# XMC1100 register map
Vendor: Infineon; File version: 1.2.2 (Reference Manual v1.2)
CPU: CM0 r0p0, little endian, no MPU, no FPU, 2 interrupt priority bits
Registers are 32-bit, read-write, reset 0x0 unless marked. A register's access mark holds for its fields unless they carry their own. Offsets are from the block's base; [hi:lo] are bit positions; {n}, {i} and the like mark numbered series; 'fields as' and 'values as' point back to an identical list.

## PORT0
Base 0x40040000
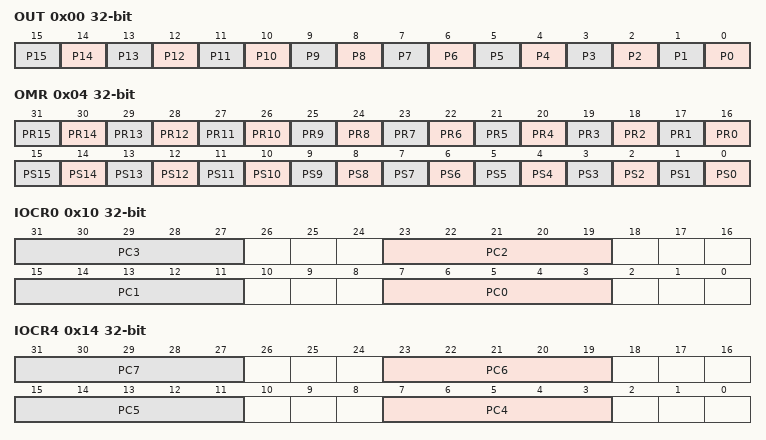
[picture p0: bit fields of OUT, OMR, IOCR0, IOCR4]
0x00 OUT — Port 0 Output Register
  [all] fields
    0=The output level of P0.x is 0; 1=The output level of P0.x is 1
  [n] P{n} (n=0..15) — Port 0 Output Bit {n}
0x04 OMR wo — Port 0 Output Modification Register
  [n+16] PR{n} (n=0..15) — Port 0 Reset Bit {n}
  [n] PS{n} (n=0..15) — Port 0 Set Bit {n}
0x10 IOCR0 — Port 0 Input/Output Control Register 0
  [all] fields
    0=Input - No internal pull device active; 1=Input - Internal pull-down device active; 2=Input - Internal pull-up device active; 3=Input - No internal pull device, Pn_OUTx = input value; 4=Input inverted - No internal pull device active; 5=Input inverted - Internal pull-down device active; 6=Input inverted - Internal pull-up device active; 7=Input inverted - No internal pull device, Pn_OUTx = input value; 16=Output Push-Pull - General-purpose output; {v}=Output Push-Pull - Alternate output function {v-16} (v=17..23); 24=Output Open Drain - General-purpose output; {v}=Output Open Drain - Alternate output function {v-24} (v=25..31)
  [8n+7:8n+3] PC{n} (n=0..3) — Port Control for Port n Pin 0 to 3
0x14 IOCR4 — Port 0 Input/Output Control Register 4
  [all] fields
    values as the fields of IOCR0
  [8n-25:8n-29] PC{n} (n=4..7) — Port Control for Port n Pin 4 to 7
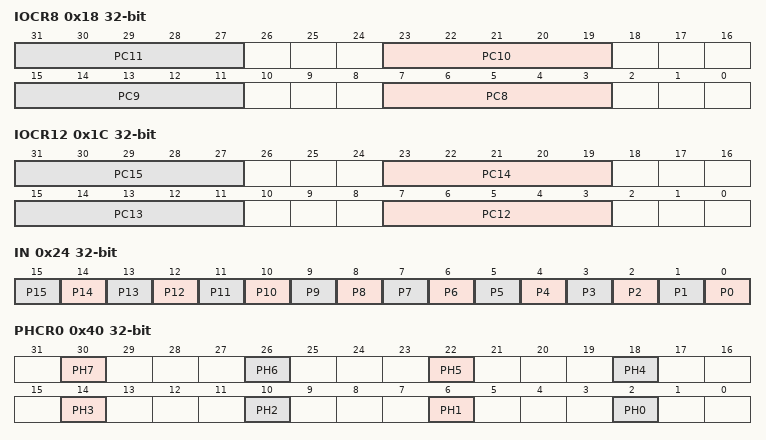
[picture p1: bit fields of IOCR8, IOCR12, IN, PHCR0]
0x18 IOCR8 — Port 0 Input/Output Control Register 8
  [all] fields
    values as the fields of IOCR0
  [8n-57:8n-61] PC{n} (n=8..11) — Port Control for Port n Pin 8 to 11
0x1C IOCR12 — Port 0 Input/Output Control Register 12
  [all] fields
    values as the fields of IOCR0
  [8n-89:8n-93] PC{n} (n=12..15) — Port Control for Port n Pin 12 to 15
0x24 IN ro (reset mask 0xFFFF0000) — Port 0 Input Register
  [all] fields
    0=The input level of P0.x is 0; 1=The input level of P0.x is 1
  [n] P{n} (n=0..15) — Port 0 Input Bit {n}
0x40 PHCR0 — Port 0 Pad Hysteresis Control Register 0
  [30] PH7 — Pad Hysteresis for Pn.7
  [26] PH6 — Pad Hysteresis for Pn.6
  [22] PH5 — Pad Hysteresis for Pn.5
  [18] PH4 — Pad Hysteresis for Pn.4
  [14] PH3 — Pad Hysteresis for Pn.3
  [10] PH2 — Pad Hysteresis for Pn.2
  [6] PH1 — Pad Hysteresis for Pn.1
  [2] PH0 — Pad Hysteresis for Pn.0
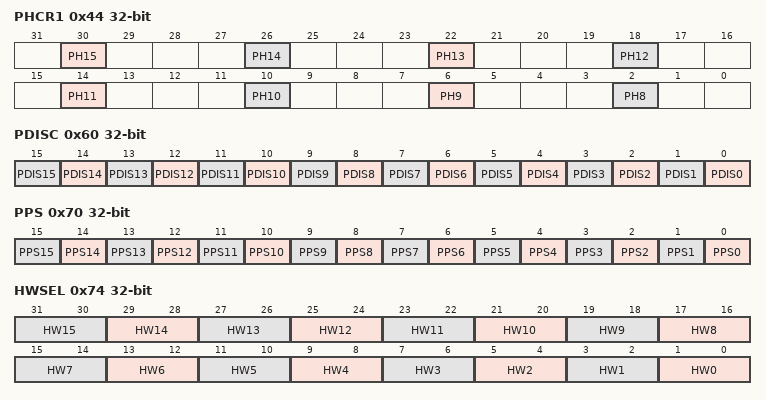
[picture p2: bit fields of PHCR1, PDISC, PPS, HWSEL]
0x44 PHCR1 — Port 0 Pad Hysteresis Control Register 1
  [30] PH15 — Pad Hysteresis for P0.15
  [26] PH14 — Pad Hysteresis for P0.14
  [22] PH13 — Pad Hysteresis for P0.13
  [18] PH12 — Pad Hysteresis for P0.12
  [14] PH11 — Pad Hysteresis for P0.11
  [10] PH10 — Pad Hysteresis for P0.10
  [6] PH9 — Pad Hysteresis for P0.9
  [2] PH8 — Pad Hysteresis for P0.8
0x60 PDISC ro (reset mask 0xFFFF0000) — Port 0 Pin Function Decision Control Register
  [all] fields
    0=Pad P0.x is enabled; 1=Pad P0.x is disabled
  [n] PDIS{n} (n=0..15) — Pad Disable for Port 0 Pin {n}
0x70 PPS — Port 0 Pin Power Save Register
  [all] fields
    0=Pin Power Save of P0.x is disabled; 1=Pin Power Save of P0.x is enabled
  [n] PPS{n} (n=0..15) — Port 0 Pin Power Save Bit {n}
0x74 HWSEL — Port 0 Pin Hardware Select Register
  [all] fields
    0=Software control only; 1=HW0 control path can override the software configuration; 2=HW1 control path can override the software configuration
  [2n+1:2n] HW{n} (n=0..15) — Port 0 Pin Hardware Select Bit {n}

## PORT1
Base 0x40040100
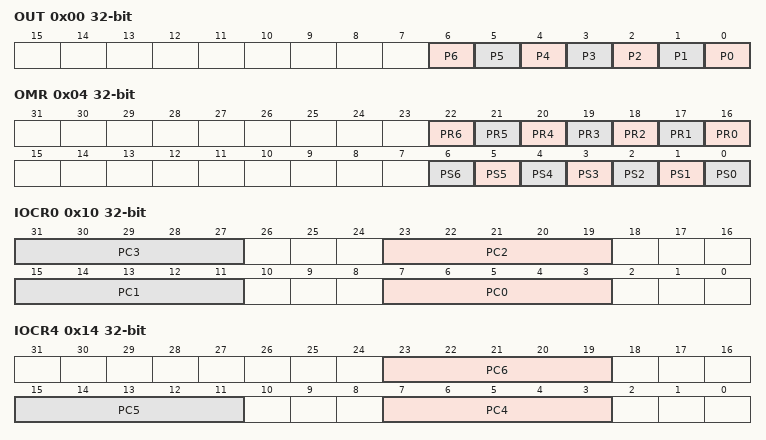
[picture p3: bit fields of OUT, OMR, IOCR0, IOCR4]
0x00 OUT — Port 1 Output Register
  [all] fields
    0=The output level of P1.x is 0; 1=The output level of P1.x is 1
  [n] P{n} (n=0..6) — Port 1 Output Bit {n}
0x04 OMR wo — Port 1 Output Modification Register
  [n+16] PR{n} (n=0..6) — Port 1 Reset Bit {n}
  [n] PS{n} (n=0..6) — Port 1 Set Bit {n}
0x10 IOCR0 — Port 1 Input/Output Control Register 0
  [all] fields
    0=Input - No internal pull device active; 1=Input - Internal pull-down device active; 2=Input - Internal pull-up device active; 3=Input - No internal pull device, Pn_OUTx = input value; 4=Input inverted - No internal pull device active; 5=Input inverted - Internal pull-down device active; 6=Input inverted - Internal pull-up device active; 7=Input inverted - No internal pull device, Pn_OUTx = input value; 16=Output Push-Pull - General-purpose output; {v}=Output Push-Pull - Alternate output function {v-16} (v=17..23); 24=Output Open Drain - General-purpose output; {v}=Output Open Drain - Alternate output function {v-24} (v=25..31)
  [8n+7:8n+3] PC{n} (n=0..3) — Port Control for Port n Pin 0 to 3
0x14 IOCR4 — Port 1 Input/Output Control Register 4
  [all] fields
    values as the fields of IOCR0
  [23:19] PC6 — Port Control for Port n Pin 4 to 6
  [15:11] PC5 — Port Control for Port n Pin 4 to 6
  [7:3] PC4 — Port Control for Port n Pin 4 to 6
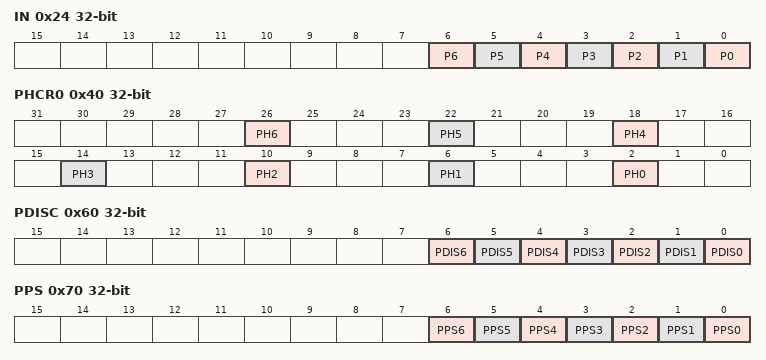
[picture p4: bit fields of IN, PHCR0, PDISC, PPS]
0x24 IN ro (reset mask 0xFFFFFF00) — Port 1 Input Register
  [all] fields
    0=The input level of P1.x is 0; 1=The input level of P1.x is 1
  [n] P{n} (n=0..6) — Port 1 Input Bit {n}
0x40 PHCR0 — Port 1 Pad Hysteresis Control Register 0
  [26] PH6 — Pad Hysteresis for P1.6
  [22] PH5 — Pad Hysteresis for P1.5
  [18] PH4 — Pad Hysteresis for P1.4
  [14] PH3 — Pad Hysteresis for P1.3
  [10] PH2 — Pad Hysteresis for P1.2
  [6] PH1 — Pad Hysteresis for P1.1
  [2] PH0 — Pad Hysteresis for P1.0
0x60 PDISC ro (reset mask 0xFFFFFF00) — Port 1 Pin Function Decision Control Register
  [all] fields
    0=Pad P1.x is enabled; 1=Pad P1.x is disabled
  [n] PDIS{n} (n=0..6) — Pad Disable for Port 1 Pin {n}
0x70 PPS — Port 1 Pin Power Save Register
  [all] fields
    0=Pin Power Save of P1.x is disabled; 1=Pin Power Save of P1.x is enabled
  [n] PPS{n} (n=0..6) — Port 1 Pin Power Save Bit {n}
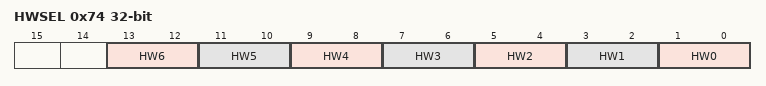
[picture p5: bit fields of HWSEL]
0x74 HWSEL — Port 1 Pin Hardware Select Register
  [all] fields
    0=Software control only; 1=HW0 control path can override the software configuration; 2=HW1 control path can override the software configuration
  [2n+1:2n] HW{n} (n=0..6) — Port 1 Pin Hardware Select Bit {n}

## PORT2
Base 0x40040200
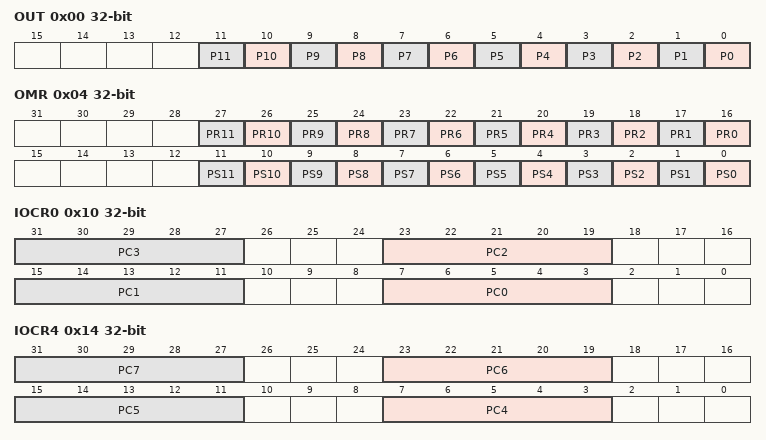
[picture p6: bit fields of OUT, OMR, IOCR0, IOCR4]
0x00 OUT — Port 2 Output Register
  [all] fields
    0=The output level of P2.x is 0; 1=The output level of P2.x is 1
  [n] P{n} (n=0..11) — Port 2 Output Bit {n}
0x04 OMR wo — Port 2 Output Modification Register
  [n+16] PR{n} (n=0..11) — Port 2 Reset Bit {n}
  [n] PS{n} (n=0..11) — Port 2 Set Bit {n}
0x10 IOCR0 — Port 2 Input/Output Control Register 0
  [all] fields
    0=Input - No internal pull device active; 1=Input - Internal pull-down device active; 2=Input - Internal pull-up device active; 3=Input - No internal pull device, Pn_OUTx = input value; 4=Input inverted - No internal pull device active; 5=Input inverted - Internal pull-down device active; 6=Input inverted - Internal pull-up device active; 7=Input inverted - No internal pull device, Pn_OUTx = input value; 16=Output Push-Pull - General-purpose output; {v}=Output Push-Pull - Alternate output function {v-16} (v=17..23); 24=Output Open Drain - General-purpose output; {v}=Output Open Drain - Alternate output function {v-24} (v=25..31)
  [8n+7:8n+3] PC{n} (n=0..3) — Port Control for Port n Pin 0 to 3
0x14 IOCR4 — Port 2 Input/Output Control Register 4
  [all] fields
    values as the fields of IOCR0
  [8n-25:8n-29] PC{n} (n=4..7) — Port Control for Port n Pin 4 to 7
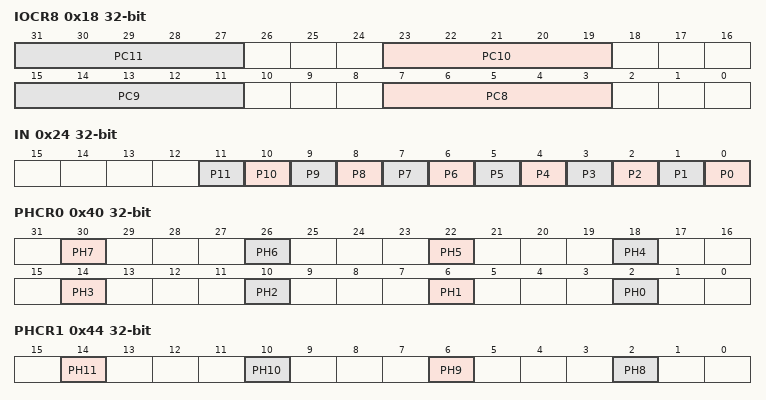
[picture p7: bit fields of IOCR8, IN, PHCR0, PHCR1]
0x18 IOCR8 — Port 2 Input/Output Control Register 8
  [all] fields
    values as the fields of IOCR0
  [8n-57:8n-61] PC{n} (n=8..11) — Port Control for Port n Pin 8 to 11
0x24 IN ro (reset mask 0xFFFFF000) — Port 2 Input Register
  [all] fields
    0=The input level of P2.x is 0; 1=The input level of P2.x is 1
  [n] P{n} (n=0..11) — Port 2 Input Bit {n}
0x40 PHCR0 — Port 2 Pad Hysteresis Control Register 0
  [30] PH7 — Pad Hysteresis for Pn.7
  [26] PH6 — Pad Hysteresis for Pn.6
  [22] PH5 — Pad Hysteresis for Pn.5
  [18] PH4 — Pad Hysteresis for Pn.4
  [14] PH3 — Pad Hysteresis for Pn.3
  [10] PH2 — Pad Hysteresis for Pn.2
  [6] PH1 — Pad Hysteresis for Pn.1
  [2] PH0 — Pad Hysteresis for Pn.0
0x44 PHCR1 — Port 2 Pad Hysteresis Control Register 1
  [14] PH11 — Pad Hysteresis for P2.11
  [10] PH10 — Pad Hysteresis for P2.10
  [6] PH9 — Pad Hysteresis for P2.9
  [2] PH8 — Pad Hysteresis for P2.8
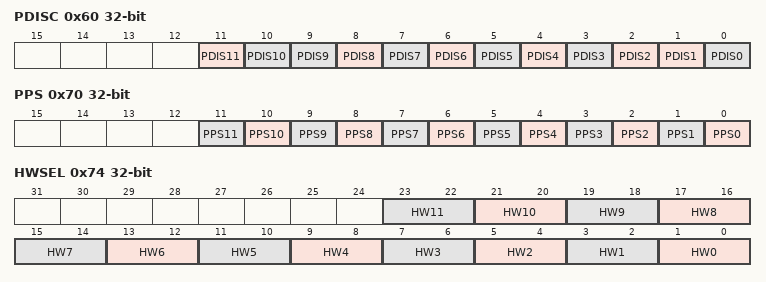
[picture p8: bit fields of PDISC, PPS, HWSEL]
0x60 PDISC (reset mask 0xFFFFF000) — Port 2 Pin Function Decision Control Register
  [11] PDIS11 — Pad Disable for Port 2 Pin 11
    0=Digital Pad input is enabled. Analog and digital input/output path active.; 1=Digital Pad input is disabled. Analog input path active. (default)
  [10] PDIS10 — Pad Disable for Port 2 Pin 10
    values as PDIS11
  [n] PDIS{n} (n=2..9) — Pad Disable for Port 2 Pin {n}
    0=Digital Pad input is enabled. Analog and digital input path active.; 1=Digital Pad input is disabled. Analog input path active. (default)
  [1] PDIS1 — Pad Disable for Port 2 Pin 1
    values as PDIS11
  [0] PDIS0 — Pad Disable for Port 2 Pin 0
    values as PDIS11
0x70 PPS — Port 2 Pin Power Save Register
  [all] fields
    0=Pin Power Save of P2.x is disabled; 1=Pin Power Save of P2.x is enabled
  [n] PPS{n} (n=0..11) — Port 2 Pin Power Save Bit {n}
0x74 HWSEL — Port 2 Pin Hardware Select Register
  [all] fields
    0=Software control only; 1=HW0 control path can override the software configuration; 2=HW1 control path can override the software configuration
  [2n+1:2n] HW{n} (n=0..11) — Port 2 Pin Hardware Select Bit {n}
